# CC1314R10 register map
File version: 1.0
CPU: CM33 1.0, other endian, MPU, FPU, 3 interrupt priority bits
Registers are 32-bit, read-write, reset 0x0 unless marked. A register's access mark holds for its fields unless they carry their own. Offsets are from the block's base; [hi:lo] are bit positions; lines under a group give offsets from that group; {n}, {i} and the like mark numbered series; 'fields as' and 'values as' point back to an identical list.

## NVMNW (part 2 of 2)
Base 0x58032000
0x16C CMDDATA15 reset 0xFFFFFFFF — Command Data Register 15 This register forms the data for a command. For DATAWIDTH == 128:This register represents bits 127:96 of flash word data register 3. For DATAWIDTH == 64:This register represents bits 63:32 of flash word data register 7. This register is blocked for writes after a 1 is written to the CMDEXEC register and prior to STATCMD.DONE being set by the NoWrapper hardware. This register is used to aggregate masking for bits that do not require additional program pulses during program operations, and will be written to all 1 after the completion of all NoWrapper commands. Use cases for the CMDDATA* registers are as follows: 1)Program - These registers contain the data to be programmed. 2)Erase - These registers are not used. 3)Read Verify - These registers contain data to be verified.
  [31:0] VAL — [31:0] A 32-bit data value is placed in this field.
    0xFFFFFFFF=MAXIMUM (Maximum value of VAL); 0=MINIMUM (Minimum value of VAL)
0x1D0 CMDWEPROTA reset 0xFFFFFFFF — Command WriteErase Protect A Register This register allows the first 32 sectors of the main region to be protected from program or erase, with 1 bit protecting each sector. If the main region size is smaller than 32 sectors, then this register provides protection for the whole region. This register is blocked for writes after a 1 is written to the CMDEXEC register and prior to STATCMD.DONE being set by the NoWrapper hardware. In addition, this register is used to aggregate masking for sectors that do not require additional erase pulses during bank erase operations, and will be written to all 1 after the completion of all NoWrapper commands.
  [31:0] VAL — [31:0] Each bit protects 1 sector. bit [0]:When 1, sector 0 of the flash memory will be protected from program and erase. bit [1]:When 1, sector 1 of the flash memory will be protected from program and erase. : : bit [31]:When 1, sector 31 of the flash memory will be protected from program and erase.
    values as CMDDATA15.VAL
0x1D4 CMDWEPROTB reset 0xFFFFFFFF — Command WriteErase Protect B Register This register allows main region sectors to be protected from program and erase. Each bit corresponds to a group of 8 sectors. There are 3 cases for how these protect bits are applied: 1. Single-bank system: In the case where only a single flash bank is present, the first 32 sectors are protected via the CMDWEPROTA register. Thus, the protection give by the bits in CMDWEPROTB begin with sector 32. 2. Multi-bank system, Bank 0: When multiple flash banks are present, the first 32 sectors of bank 0 are protected via the CMDWEPROTA register. Thus, only bits 4 and above of CMDWEPROTB would be applicable to bank 0. The protection of bit 4 and above would begin at sector 32. Bits 3:0 of WEPROTB are ignored for bank 0. 3. Multi-bank system, Banks 1-N: For banks other than bank 0 in a multi-bank system, CMDWEPROTA has no effect, so the bits in CMDWEPROTB will protect these banks starting from sector 0. This register is blocked for writes after a 1 is written to the CMDEXEC register and prior to STATCMD.DONE being set by the NoWrapper hardware. In addition, this register is used to aggregate masking for sectors that do not require additional erase pulses during bank erase operations, and will be written to all 1 after the completion of all NoWrapper commands.
  [31:0] VAL — [31:0] Each bit protects a group of 8 sectors. When a bit is 1, the associated 8 sectors in the flash will be protected from program and erase. A maximum of 256 sectors can be protected with this register.
    values as CMDDATA15.VAL
0x210 CMDWEPROTNM reset 0x1 — Command WriteErase Protect Non-Main Register This register allows non-main region region sectors to be protected from program and erase. Each bit corresponds to 1 sector. This register is blocked for writes after a 1 is written to the CMDEXEC register and prior to STATCMD.DONE being set by the NoWrapper hardware. In addition, this register is used to aggregate masking for sectors that do not require additional erase pulses during bank erase operations, and will be written to all 1 after the completion of all NoWrapper commands.
  [0] VAL — [0:0] Each bit protects 1 sector. bit [0]:When 1, sector 0 of the non-main region will be protected from program and erase. bit [1]:When 1, sector 1 of the non-main region will be protected from program and erase. : : bit [31]:When 1, sector 31 of the non-main will be protected from program and erase.
    1=MAXIMUM (Maximum value of VAL); 0=MINIMUM (Minimum value of VAL)
0x214 CMDWEPROTTR reset 0x1 — Command WriteErase Protect Trim Register This register allows trim region sectors to be protected from program and erase. Each bit corresponds to 1 sector. This register is blocked for writes after a 1 is written to the CMDEXEC register and prior to STATCMD.DONE being set by the NoWrapper hardware. In addition, this register is used to aggregate masking for sectors that do not require additional erase pulses during bank erase operations, and will be written to all 1 after the completion of all NoWrapper commands.
  [0] VAL — [0:0] Each bit protects 1 sector. bit [0]:When 1, sector 0 of the engr region will be protected from program and erase. bit [1]:When 1, sector 1 of the engr region will be protected from program and erase. : : bit [31]:When 1, sector 31 of the engr region will be protected from program and erase.
    values as CMDWEPROTNM.VAL
0x218 CMDWEPROTEN reset 0x1 — Command WriteErase Protect Engr Register This register allows engr region sectors to be protected from program and erase. Each bit corresponds to 1 sector. This register is blocked for writes after a 1 is written to the CMDEXEC register and prior to STATCMD.DONE being set by the NoWrapper hardware. In addition, this register is used to aggregate masking for sectors that do not require additional erase pulses during bank erase operations, and will be written to all 1 after the completion of all NoWrapper commands.
  fields as CMDWEPROTTR
0x3B0 CFGCMD reset 0x2 — Command Configuration Register This register configures specific capabilities of the state machine for related to the execution of a command. This register is blocked for writes after CMDEXEC is written to a 1 and prior to STATCMD.DONE being set by the hardware to indicate that command execution has completed.
  [3:0] WAITSTATE — [3:0] Wait State setting for program verify, erase verify and read verify
    15=MAXIMUM (Maximum value); 0=MINIMUM (Minimum value)
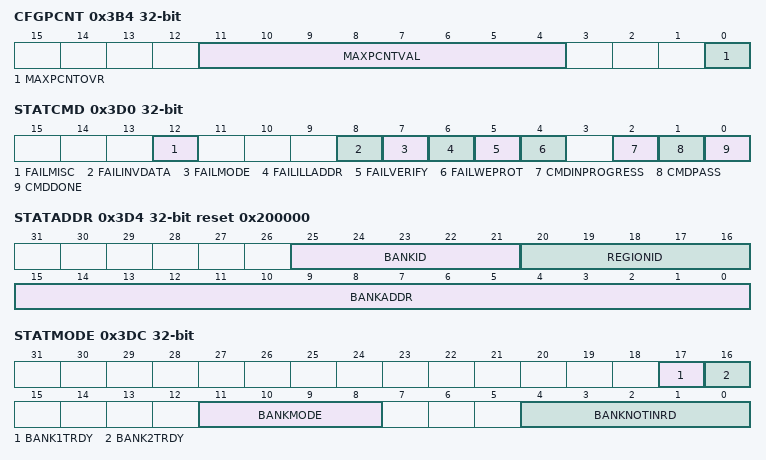
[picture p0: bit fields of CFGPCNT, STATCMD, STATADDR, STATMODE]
0x3B4 CFGPCNT — Pulse Counter Configuration Register This register allows further configuration of maximum pulse counts for program and erase operations. This register is blocked for writes after a 1 is written to the CMDEXEC register and prior to STATCMD.DONE being set by the NoWrapper hardware.
  [11:4] MAXPCNTVAL — [11:4] Override maximum pulse counter with this value. If MAXPCNTOVR = 0, then this field is ignored. If MAXPCNTOVR = 1 and MAXERSPCNTOVR = 0, then this value will be used to override the max pulse count for both program and erase. Full max value will be {4'h0, MAXPCNTVAL} . If MAXPCNTOVR = 1 and MAXERSPCNTOVR = 1, then this value will be used to override the max pulse count for program only. Full max value will be {4'h0, MAXPCNTVAL}.
    255=MAXIMUM (Maximum value); 0=MINIMUM (Minimum value)
  [0] MAXPCNTOVR — [0:0] Override hard-wired maximum pulse count. If MAXERSPCNTOVR is not set, then setting this value alone will override the max pulse count for both program and erase. If MAXERSPCNTOVR is set, then this bit will only control the max pulse count setting for program. By default, this bit is 0, and a hard-wired max pulse count is used.
    1=OVERRIDE (Use value from MAXPCNTVAL field as maximum puse count); 0=DEFAULT (Use hard-wired (default) value for maximum pulse count)
0x3D0 STATCMD — Command Status Register This register contains status regarding completion and errors of command execution.
  [12] FAILMISC ro — [12:12] Command failed due to error other than write/erase protect violation or verify error. This is an extra bit in case a new failure mechanism is added which requires a status bit.
    1=STATFAIL (Fail); 0=STATNOFAIL (No Fail)
  [8] FAILINVDATA ro — [8:8] Program command failed because an attempt was made to program a stored 0 value to a 1.
    1=STATFAIL (Fail); 0=STATNOFAIL (No Fail)
  [7] FAILMODE ro — [7:7] Command failed because a bank has been set to a mode other than READ. Program and Erase commands cannot be initiated unless all banks are in READ mode.
    1=STATFAIL (Fail); 0=STATNOFAIL (No Fail)
  [6] FAILILLADDR ro — [6:6] Command failed due to the use of an illegal address
    1=STATFAIL (Fail); 0=STATNOFAIL (No Fail)
  [5] FAILVERIFY ro — [5:5] Command failed due to verify error
    1=STATFAIL (Fail); 0=STATNOFAIL (No Fail)
  [4] FAILWEPROT ro — [4:4] Command failed due to Write/Erase Protect Sector Violation
    1=STATFAIL (Fail); 0=STATNOFAIL (No Fail)
  [2] CMDINPROGRESS ro — [2:2] Command In Progress
    1=STATINPROGRESS (In Progress); 0=STATCOMPLETE (Complete)
  [1] CMDPASS ro — [1:1] Command Pass - valid when CMD_DONE field is 1
    1=STATPASS (Pass); 0=STATFAIL (Fail)
  [0] CMDDONE ro — [0:0] Command Done
    1=STATDONE (Done); 0=STATNOTDONE (Not Done)
0x3D4 STATADDR reset 0x200000 — Current Address Counter Value Read only register giving read access to the state machine current address. A bank id, region id and address are stored in this register and are incremented as necessary during execution of a command.
  [25:21] BANKID ro — [25:21] Current Bank ID A bank indicator is stored in this register which represents the current bank on which the state machine is operating. There is 1 bit per bank.
    16=BANK4; 8=BANK3; 4=BANK2; 2=BANK1; 1=BANK0
  [20:16] REGIONID ro — [20:16] Current Region ID A region indicator is stored in this register which represents the current flash region on which the state machine is operating.
    8=ENGR (Engr Region); 4=TRIM (Trim Region); 2=NONMAIN (Non-Main Region); 1=MAIN (Main Region)
  [15:0] BANKADDR ro — [15:0] Current Bank Address A bank offset address is stored in this register.
    0xFFFF=MAXIMUM (Maximum value); 0=MINIMUM (Minimum value)
0x3D8 STATPCNT — Current Pulse Count Register: Read only register giving read access to the state machine current pulse count value for program/erase operations.
  [11:0] PULSECNT ro — [11:0] Current Pulse Counter Value
    0xFFF=MAXIMUM (Maximum value); 0=MINIMUM (Minimum value)
0x3DC STATMODE — Mode Status Register Indicates any banks which not in READ mode, and it indicates the mode which the bank(s) are in.
  [17] BANK1TRDY ro — [17:17] Bank 1T Ready. Bank(s) are ready for 1T access. This is accomplished when the bank and pump have been trimmed.
    1=TRUE (Ready); 0=FALSE (Not ready)
  [16] BANK2TRDY ro — [16:16] Bank 2T Ready. Bank(s) are ready for 2T access. This is accomplished when the pump has fully driven power rails to the bank(s).
    1=TRUE (Ready); 0=FALSE (Not ready)
  [11:8] BANKMODE ro — [11:8] Indicates mode of bank(s) that are not in READ mode
    15=ERASEBNK (Erase Bank); 14=PGMMW (Program Multiple Word); 12=ERASESECT (Erase Sector); 11=ERASEVER (Erase Verify Mode); 10=PGMSW (Program Single Word); 9=PGMVER (Program Verify Mode); 7=RDMARG1B (Read Margin 1B Mode); 6=RDMARG0B (Read Margin 0B Mode); 4=RDMARG1 (Read Margin 1 Mode); 2=RDMARG0 (Read Margin 0 Mode); 0=READ (Read Mode)
  [4:0] BANKNOTINRD ro — [4:0] Bank not in read mode. Indicates which banks are not in READ mode. There is 1 bit per bank.
    16=BANK4; 8=BANK3; 4=BANK2; 2=BANK1; 1=BANK0
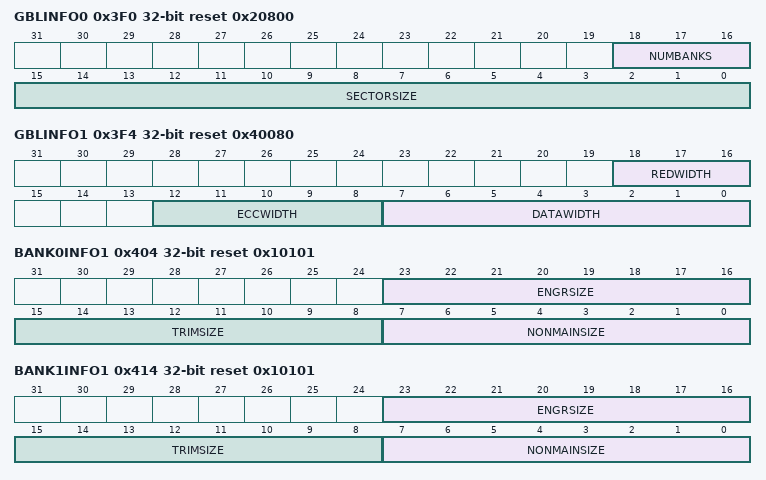
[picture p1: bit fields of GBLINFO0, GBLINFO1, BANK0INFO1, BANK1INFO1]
0x3F0 GBLINFO0 reset 0x20800 — Global Info 0 Register Read only register detailing information about sector size and number of banks present.
  [18:16] NUMBANKS ro — [18:16] Number of banks instantiated Minimum:1 Maximum:5
    5=MAXIMUM (Maximum value); 1=MINIMUM (Minimum value)
  [15:0] SECTORSIZE ro — [15:0] Sector size in bytes
    0x800=TWOKB (Sector size is TWOKB); 0x400=ONEKB (Sector size is ONEKB)
0x3F4 GBLINFO1 reset 0x40080 — Global Info 1 Register Read only register detailing information about data, ecc and redundant data widths in bits.
  [18:16] REDWIDTH ro — [18:16] Redundant data width in bits
    4=W4BIT (Redundant data width is 4 bits); 2=W2BIT (Redundant data width is 2 bits); 0=W0BIT (Redundant data width is 0. Redundancy/Repair not present.)
  [12:8] ECCWIDTH ro — [12:8] ECC data width in bits
    16=W16BIT (ECC data width is 16 bits); 8=W8BIT (ECC data width is 8 bits); 0=W0BIT (ECC data width is 0. ECC not used.)
  [7:0] DATAWIDTH ro — [7:0] Data width in bits
    128=W128BIT (Data width is 128 bits); 64=W64BIT (Data width is 64 bits)
0x3F8 GBLINFO2 reset 0x4 — Global Info 2 Register Read only register detailing information about the number of data registers present.
  [3:0] DATAREGISTERS ro — [3:0] Number of data registers present.
    8=MAXIMUM (Maximum value of DATAREGISTERS); 1=MINIMUM (Minimum value of DATAREGISTERS)
0x400 BANK0INFO0 reset 0x100 — Bank Info 0 Register for bank 0. Read only register detailing information about Main region size in the bank.
  [11:0] MAINSIZE ro — [11:0] Main region size in sectors Minimum:0x8 (8) Maximum:0x200 (512)
    0x200=MAXSECTORS (Maximum value of MAINSIZE); 8=MINSECTORS (Minimum value of MAINSIZE)
0x404 BANK0INFO1 reset 0x10101 — Bank Info1 Register for bank 0. Read only register detailing information about Non-Main, Trim, and Engr region sizes in the bank.
  [23:16] ENGRSIZE ro — [23:16] Engr region size in sectors Minimum:0x0 (0) Maximum:0x10 (16)
    32=MAXSECTORS (Maximum value of ENGRSIZE); 0=MINSECTORS (Minimum value of ENGRSIZE)
  [15:8] TRIMSIZE ro — [15:8] Trim region size in sectors Minimum:0x0 (0) Maximum:0x10 (16)
    32=MAXSECTORS (Maximum value of TRIMSIZE); 0=MINSECTORS (Minimum value of TRIMSIZE)
  [7:0] NONMAINSIZE ro — [7:0] Non-main region size in sectors Minimum:0x0 (0) Maximum:0x10 (16)
    32=MAXSECTORS (Maximum value of NONMAINSIZE); 0=MINSECTORS (Minimum value of NONMAINSIZE)
0x410 BANK1INFO0 reset 0x100 — Bank Info 0 Register for bank 1. Read only register detailing information about Main region size in the bank.
  fields as BANK0INFO0
0x414 BANK1INFO1 reset 0x10101 — Bank Info1 Register for bank 1. Read only register detailing information about Non-Main, Trim, and Engr region sizes in the bank.
  [23:16] ENGRSIZE ro — [23:16] Engr region size in sectors Minimum:0x0 (0) Maximum:0x10 (16)
    values as BANK0INFO1.ENGRSIZE
  [15:8] TRIMSIZE ro — [15:8] Trim region size in sectors
    values as BANK0INFO1.TRIMSIZE
  [7:0] NONMAINSIZE ro — [7:0] Non-main region size in sectors
    values as BANK0INFO1.NONMAINSIZE
0x500 DFTEN — DFT Enable Register Allows control of NoWrapper test features. When set, DFT* registers in this aperture open for write access. When cleared, DFT* registers are read-only. This register is blocked for writes after a 1 is written to the CMDEXEC register and prior to STATCMD.DONE being set by the NoWrapper hardware.
  [0] ENABLE — [0:0] Enable Test Features
    1=ENABLED (Command); 0=DISABLED (Command)
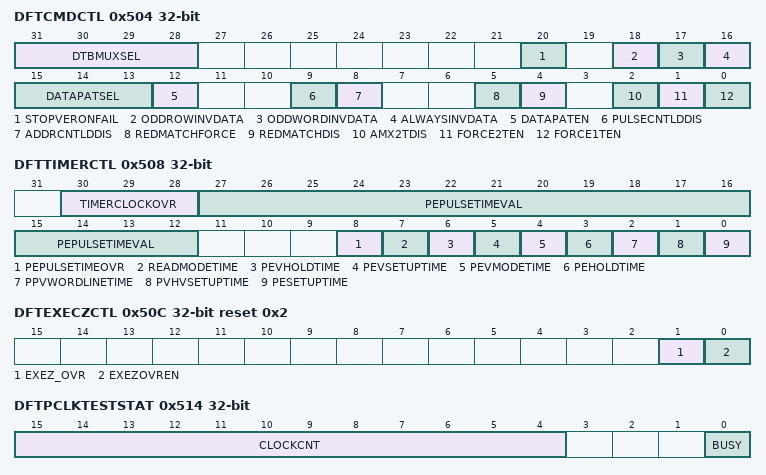
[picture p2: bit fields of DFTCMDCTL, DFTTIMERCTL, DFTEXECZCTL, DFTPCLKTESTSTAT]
0x504 DFTCMDCTL — DFT Command Control Register This register configures specific capabilities for test. This register is only writable when DFTEN.ENABLE is set. This register is blocked for writes after a 1 is written to the CMDEXEC register and prior to STATCMD.DONE being set by the NoWrapper hardware.
  [31:28] DTBMUXSEL — [31:28] DTB Mux Select This field will form the select for the primary DTB mux. This mux selects up to 16 sets of 32-bit fields of internal signals to be present to the 32-bit DTB output.
    15=MAXIMUM (Maximum value); 0=MINIMUM (Minimum value)
  [20] STOPVERONFAIL — [20:20] Stop read verify on fail. If this bit is set, read verify will halt when the first verify fail is detected. If command is program or erase, another program or erase pulse will be executed. If command is read verify, comand will terminate.
    1=ENABLE; 0=DISABLE
  [18] ODDROWINVDATA — [18:18] Invert data at odd row addresses for program or verify. The LSB of the row address is bit [4] of the bank address. This bit only applies when pattern data is used; i.e. the DATAPATEN bit is set. It will have no effect if CMDDATA is used.
    1=INVERT (Use inverted data); 0=TRUE (Use true data)
  [17] ODDWORDINVDATA — [17:17] Invert data at odd bank addresses for program or verify. This bit only applies when pattern data is used; i.e. the DATAPATEN bit is set. It will have no effect if CMDDATA is used.
    1=INVERT (Use inverted data); 0=TRUE (Use true data)
  [16] ALWAYSINVDATA — [16:16] Invert data always for program or verify. This bit only applies when pattern data is used; i.e. the DATAPATEN bit is set. It will have no effect if CMDDATA is used.
    1=INVERT (Use inverted data); 0=TRUE (Use true data)
  [15:13] DATAPATSEL — [15:13] Select data pattern. Valid when DATAPATEN bit is set to 1. Overrides CMDDATA registers for program or verify.
    2=LOGCHKBRD (Set to logical checkerboard (0x01010101...)); 1=ALL1 (Set to all 1); 0=ALL0 (Set to all 0)
  [12] DATAPATEN — [12:12] Enable data pattern. Data pattern select in DATAPATSEL field will override data from CMDDATA registers for use as program or verify data.
    1=ENABLE; 0=DISABLE
  [9] PULSECNTLDDIS — [9:9] Override pulse counter enable. When set, the state machine pulse counter will not be loaded when a command is initiated.
    1=DISABLE; 0=ENABLE
  [8] ADDRCNTLDDIS — [8:8] Override address counter enable. When set, the state machine address counter will not be loaded when a command is initiated.
    1=DISABLE; 0=ENABLE
  [5] REDMATCHFORCE — [5:5] Force redundancy match. If set to 1, repair configuration encoded in the flash bank trim will be forced for every access.
    1=ENABLE; 0=DISABLE
  [4] REDMATCHDIS — [4:4] Disable redundancy matching. Any repair configuration encoded into the bank trim bits is disabled.
    1=DISABLE; 0=ENABLE
  [2] AMX2TDIS — [2:2] 2T address mux disable control. When set to 1 2T address shifting is disabled. This bit should only be enabled for reads. Indeterminate behavior will result if this bit is set during program/erase. Furthermore, only reads done via a READVERIFY command will be guaranteed to work properly. Reads via the FBAP port are not guaranteed to operate.
    1=DISABLE; 0=ENABLE
  [1] FORCE2TEN — [1:1] Force 2T Enable - Force 2T access to regions that are designated as 1T. Regions designated as 2T will still be accessed as 2T.
    1=ENABLE; 0=DISABLE
  [0] FORCE1TEN — [0:0] Force 1T Enable - Force 1T access to regions that are designated as 2T. Regions designated as 1T will still be accessed as 1T.
    1=ENABLE; 0=DISABLE
0x508 DFTTIMERCTL — DFT Timer Control Register This allows some configuration of timing values for various phases of flash operations for test. These time values are hard-coded for functional execution. This register is only writable when DFT.ENABLE is set. This register is blocked for writes after a 1 is written to the CMDEXEC register and prior to STATCMD.DONE being set by the NoWrapper hardware.
  [30:28] TIMERCLOCKOVR — [30:28] Override Timer clock frequency using an ICG-based clock divide mechanism. To divide the timer clock, pulses can be skipped based on settings in this field. By default, this field is 0, which corresponds to no division on the timer clock.
    {v}=DIVIDEBY{v+1} (Divide timer clock by {v+1}) (v=1..7); 0=NODIVIDE (No divide on timer clock.)
  [27:12] PEPULSETIMEVAL — [27:12] Program/Erase Pulse Time Value If operation is a program, this value gets loaded into bits [15:0] of the timer when the PEPULSETIMEVALOVR field is set to 1. If operation is an erase, this value gets loaded into bits [19:4] of the timer when the PEPULSETIMEVALOVR field is set to 1.
    0xFFFF=MAXIMUM (Maximum value); 1=MINIMUM (Minimum value)
  [8] PEPULSETIMEOVR — [8:8] Override Program/Erase Pulse Time If set, this will force the program or erase pulse time to be overridden with the value in the PEPULSETIMEVAL field. If not set, then a hard-coded value will be used for this pulse time.
    1=OVERRIDE (Use value from the PE_PULSE_TIME field for time value); 0=FUNCTIONAL (Use hard-wired (Functional) timer value)
  [7] READMODETIME — [7:7] Read Mode Change Time
    1=TWOXFUNCTIONAL (Use 2x the hard-wired (functional) time value); 0=FUNCTIONAL (Use hard-wired (Functional) timer value)
  [6] PEVHOLDTIME — [6:6] Program/Erase Verify Hold Time
    values as READMODETIME
  [5] PEVSETUPTIME — [5:5] Program/Erase Verify Setup Time
    values as READMODETIME
  [4] PEVMODETIME — [4:4] Program/Erase Verify Mode Change Time
    values as READMODETIME
  [3] PEHOLDTIME — [3:3] Program/Erase Hold Time
    values as READMODETIME
  [2] PPVWORDLINETIME — [2:2] Program and Program Verify Wordline Switching Time
    values as READMODETIME
  [1] PVHVSETUPTIME — [1:1] Program VHV Setup Time
    values as READMODETIME
  [0] PESETUPTIME — [0:0] Program/Erase Setup Time
    values as READMODETIME
0x50C DFTEXECZCTL reset 0x2 — DFT EXECUTEZ control register. This register allows direct control of the EXECUTEZ to bank and pump for test. This register is only writable when DFTEN.ENABLE is set. This register is blocked for writes after a 1 is written to the CMDEXEC register and prior to STATCMD.DONE being set by the NoWrapper hardware.
  [1] EXEZ_OVR — [1:1] Override value to be applied to EXECUTEZ
    1=ONE (Set EXECUTEZ to 1); 0=ZERO (Set EXECUTEZ to 0)
  [0] EXEZOVREN — [0:0] Enable override of EXECUTEZ Note that when this bit is set, NoWrapper has control of the bank pins.
    1=ENABLE; 0=DISABLE
0x510 DFTPCLKTESTCTL — DFT Pump Clock Test Control Register. This register controls hardware features that allow the pump clock to be characterized for trim development. This register is only writable when DFTEN.ENABLE is set. This register is blocked for writes after a 1 is written to the CMDEXEC register and prior to STATCMD.DONE being set by the NoWrapper hardware.
  [0] ENABLE — [0:0] Enable the state machine which sequences measurement of pump clock frequency.
    1=ENABLE; 0=DISABLE
0x514 DFTPCLKTESTSTAT — DFT Pump Clock Test Status Register. This register shows status reported by the hardware features that allow the pump clock to be characterized for trim development. This register is only writable when DFTEN.ENABLE is set.
  [15:4] CLOCKCNT ro — [15:4] Indicates the core clock count captured during the pump clock measurement.
    0xFFF=MAXIMUM (Maximum count value); 0=MINIMUM (Minimum count value)
  [0] BUSY ro — [0:0] Indicates that a pump clock measurement is in progress.
    1=INPROGRESS (Indicates test in progress); 0=COMPLETE (Indicates test complete)
{0x540+4i} DFTDATARED{i} reset 0xF (i=0..3) — DFT Redundancy Data Register {i} This register is used when testing the redundant columns in the flash. It acts as an extension of the CMDDATA* registers. The bits in this register correspond to flash data word register {i}. In addition, this register is used to aggregate masking for bits that do not require additional program pulses during program operations. The original data written to this register will be lost during program command execution. Use cases for this register are as follows: 1)Program - Contains the data to be programmed. 2)Erase - Not used. 3)Read Verify - Contains data to be verified. This register is only writable when DFTEN.ENABLE is set. This register is blocked for writes after a 1 is written to the CMDEXEC register and prior to STATCMD.DONE being set by the NoWrapper hardware.
  [3:0] VAL — [3:0] Data for redundant bits
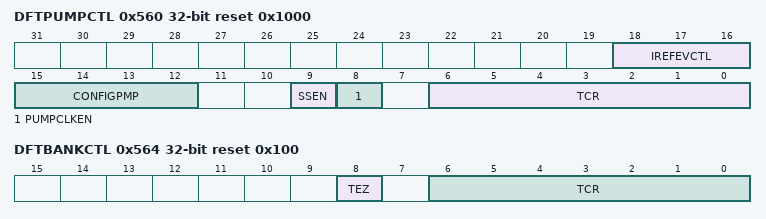
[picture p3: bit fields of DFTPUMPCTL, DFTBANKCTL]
0x560 DFTPUMPCTL reset 0x1000 — DFT Pump Control Register This allows some configuration of pump parameters during test. This register is only writable when DFTEN.ENABLE is set. This register is blocked for writes after a 1 is written to the CMDEXEC register and prior to STATCMD.DONE being set by the NoWrapper hardware.
  [18:16] IREFEVCTL — [18:16] IREFEV control IREFVRD, REFTC, IREFCONST, IREFCCOR blocks in IREFEV
  [15:12] CONFIGPMP — [15:12] Pump configuration control. LP, HP operation
  [9] SSEN — [9:9] Dither control for oscillator Enumeration: 0: Disable Dither 1: Enable Dither
    1=ENABLE; 0=DISABLE
  [8] PUMPCLKEN — [8:8] Allows direct control of the pump oscillator which is used to generate pumpclk. Normally, enable/disable of pumpclk is under NoWrapper state machine control. This bit allows system to enable the clock independently.
    1=ENABLE (Force pump clock oscillator to be enabled.); 0=HWCTL (Allow pump clock oscillator to be controlled by hardware.)
  [6:0] TCR — [6:0] TCR test mode to be applied to the pump
    127=MAXIMUM (Maximum value); 0=MINIMUM (Minimum value)
0x564 DFTBANKCTL reset 0x100 — DFT Bank Control Register This allows some configuration of bank parameters during test. This register is only writable when DFTEN.ENABLE is set. This register is blocked for writes after a 1 is written to the CMDEXEC register and prior to STATCMD.DONE being set by the NoWrapper hardware.
  [8] TEZ — [8:8] When set, TEZ is asserted to the flash banks. Which banks get the asserted signal is determined by the BANKSELECT field in CMDCTL. 0x0 Do no assert TEZ 0x1 Assert TEZ
    1=NEGATE (Do not assert TEZ); 0=ASSERT (Assert TEZ)
  [6:0] TCR — [6:0] TCR test mode to be applied to the bank
    127=MAXIMUM (Maximum value); 0=MINIMUM (Minimum value)
